AUTOSAR XML (schema 4-2-2)
package /ComponentTypes
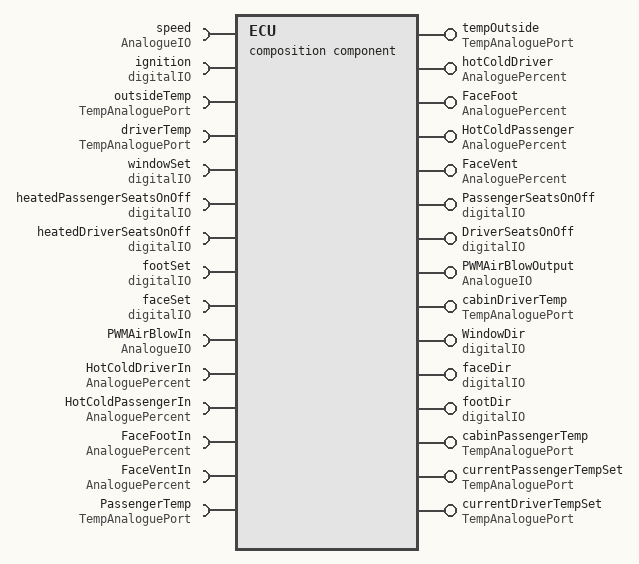
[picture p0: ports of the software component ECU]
  composition sw component type ECU
    require port speed: required-interface=AnalogueIO
    require port ignition: required-interface=digitalIO
    provide port tempOutside: provided-interface=TempAnaloguePort
    8 x require port:
      outsideTemp: required-interface=TempAnaloguePort
      driverTemp: required-interface=TempAnaloguePort
      windowSet: required-interface=digitalIO
      heatedPassengerSeatsOnOff: required-interface=digitalIO
      heatedDriverSeatsOnOff: required-interface=digitalIO
      footSet: required-interface=digitalIO
      faceSet: required-interface=digitalIO
      PWMAirBlowIn: required-interface=AnalogueIO
    11 x provide port:
      hotColdDriver: provided-interface=AnaloguePercent
      FaceFoot: provided-interface=AnaloguePercent
      HotColdPassenger: provided-interface=AnaloguePercent
      FaceVent: provided-interface=AnaloguePercent
      PassengerSeatsOnOff: provided-interface=digitalIO
      DriverSeatsOnOff: provided-interface=digitalIO
      PWMAirBlowOutput: provided-interface=AnalogueIO
      cabinDriverTemp: provided-interface=TempAnaloguePort
      WindowDir: provided-interface=digitalIO
      faceDir: provided-interface=digitalIO
      footDir: provided-interface=digitalIO
    4 x require port, all with required-interface=AnaloguePercent:
      HotColdDriverIn
      HotColdPassengerIn
      FaceFootIn
      FaceVentIn
    provide port cabinPassengerTemp: provided-interface=TempAnaloguePort
    provide port currentPassengerTempSet: provided-interface=TempAnaloguePort
    require port PassengerTemp: required-interface=TempAnaloguePort
    provide port currentDriverTempSet: provided-interface=TempAnaloguePort
    component Inputs: type=OutsideVariables
    component Input: type=HeatingVariables
    delegate Inputs.ignitionStatus <-> outer port ignition
    delegate Inputs.tempOutsideOut <-> outer port tempOutside
    delegate Inputs.TempAnaloguePort <-> outer port outsideTemp
    delegate Input.driverTemp <-> outer port driverTemp
    delegate Input.foot <-> outer port footSet
    delegate Input.face <-> outer port faceSet
    delegate Input.heatedDriverSeatsOnOff <-> outer port heatedDriverSeatsOnOff
    delegate Input.airBlow <-> outer port PWMAirBlowIn
    delegate Input.passengerTemp <-> outer port PassengerTemp
    delegate Input.heatedPassengerSeatOnOff <-> outer port heatedPassengerSeatsOnOff
    delegate Input.windowSet <-> outer port windowSet
    delegate Input.hotColdPassengerOut <-> outer port HotColdPassenger
    delegate Input.hotColdDriverOut <-> outer port hotColdDriver
    delegate Input.driverSeatsOnOffOut <-> outer port DriverSeatsOnOff
    delegate Input.passengerSeatsOnOffOut <-> outer port PassengerSeatsOnOff
    delegate Input.faceFootOut <-> outer port FaceFoot
    delegate Input.FaceVentOut <-> outer port FaceVent
    delegate Input.cabinDriverTempOut <-> outer port cabinDriverTemp
    delegate Input.PWMAirBlowOut <-> outer port PWMAirBlowOutput
    delegate Input.WindowDirButton <-> outer port WindowDir
    delegate Input.faceDirButton <-> outer port faceDir
    delegate Input.footDirButton <-> outer port footDir
    delegate Input.FaceVentInFlapPercent <-> outer port FaceVentIn
    delegate Input.HotColdPassengerFlapIn <-> outer port HotColdPassengerIn
    delegate Input.HotColdDriverFlapIn <-> outer port HotColdDriverIn
    delegate Input.FaceFootFlapIn <-> outer port FaceFootIn
    delegate Input.cabinPassengerTempOut <-> outer port cabinPassengerTemp
    delegate Inputs.speedStatus <-> outer port speed
    delegate Input.DriverTempSet <-> outer port currentPassengerTempSet
    delegate Input.passengerTempSet <-> outer port currentDriverTempSet
